VERSION "2026.2.23"

NS_ :

BS_:

BU_: ESC bms_a bms_b

BO_ 2672710145 msg1: 7 ESC
 SG_ TailByte : 48|8@1+ (1,0) [0|255] ""  ESC
 SG_ ThrottleSource : 47|1@1+ (1,0) [0|1] ""  ESC
 SG_ DirectionFlag : 46|1@1+ (1,0) [0|1] ""  ESC
 SG_ CommStatus : 45|1@1+ (1,0) [0|1] ""  ESC
 SG_ OpAmpException : 44|1@1+ (1,0) [0|1] ""  ESC
 SG_ MotorDisconnection : 43|1@1+ (1,0) [0|1] ""  ESC
 SG_ MosShortCircuit : 42|1@1+ (1,0) [0|1] ""  ESC
 SG_ MosOpen : 41|1@1+ (1,0) [0|1] ""  ESC
 SG_ Stall : 40|1@1+ (1,0) [0|1] ""  ESC
 SG_ CapacitorOverheat : 39|1@1+ (1,0) [0|1] ""  ESC
 SG_ MosOverheat : 38|1@1+ (1,0) [0|1] ""  ESC
 SG_ ThrottleNotZero : 37|1@1+ (1,0) [0|1] ""  ESC
 SG_ ThrottleLost : 36|1@1+ (1,0) [0|1] ""  ESC
 SG_ PositioningComplete : 35|1@1+ (1,0) [0|1] ""  ESC
 SG_ Overcurrent : 34|1@1+ (1,0) [0|1] ""  ESC
 SG_ Undervoltage : 33|1@1+ (1,0) [0|1] ""  ESC
 SG_ Overvoltage : 32|1@1+ (1,0) [0|1] ""  ESC
 SG_ PWM : 16|16@1+ (1,0) [0|8191] ""  ESC
 SG_ RPM : 0|16@1+ (1,0) [0|65535] "rpm"  ESC

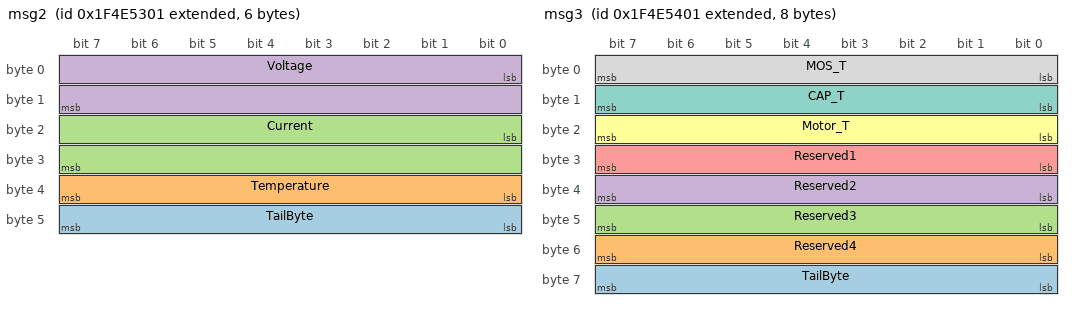
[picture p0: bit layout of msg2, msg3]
BO_ 2672710401 msg2: 6 ESC
 SG_ TailByte : 40|8@1+ (1,0) [0|255] ""  ESC
 SG_ Temperature : 32|8@1+ (1,0) [0|255] "degC"  ESC
 SG_ Current : 16|16@1+ (0.1,0) [0|6553.5] "A"  ESC
 SG_ Voltage : 0|16@1+ (0.1,0) [0|6553.5] "V"  ESC

BO_ 2672710657 msg3: 8 ESC
 SG_ TailByte : 56|8@1+ (1,0) [0|255] ""  ESC
 SG_ Reserved4 : 48|8@1+ (1,0) [0|255] ""  ESC
 SG_ Reserved3 : 40|8@1+ (1,0) [0|255] ""  ESC
 SG_ Reserved2 : 32|8@1+ (1,0) [0|255] ""  ESC
 SG_ Reserved1 : 24|8@1+ (1,0) [0|255] ""  ESC
 SG_ Motor_T : 16|8@1+ (1,0) [0|255] "degC"  ESC
 SG_ CAP_T : 8|8@1+ (1,0) [0|255] "degC"  ESC
 SG_ MOS_T : 0|8@1+ (1,0) [0|255] "degC"  ESC

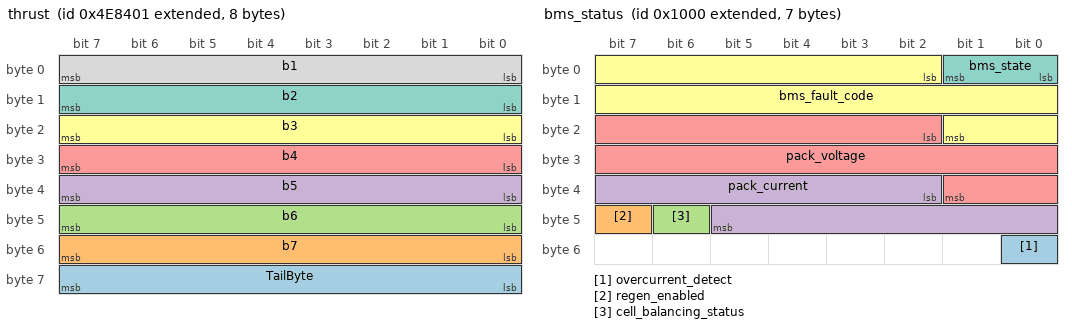
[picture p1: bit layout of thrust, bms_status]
BO_ 2152629249 thrust: 8 ESC
 SG_ TailByte : 56|8@1+ (1,0) [0|255] ""  ESC
 SG_ b7 : 48|8@1+ (1,0) [0|255] "tcode"  ESC
 SG_ b6 : 40|8@1+ (1,0) [0|255] "tcode"  ESC
 SG_ b5 : 32|8@1+ (1,0) [0|255] "tcode"  ESC
 SG_ b4 : 24|8@1+ (1,0) [0|255] "tcode"  ESC
 SG_ b3 : 16|8@1+ (1,0) [0|255] "tcode"  ESC
 SG_ b2 : 8|8@1+ (1,0) [0|255] "tcode"  ESC
 SG_ b1 : 0|8@1+ (1,0) [0|255] "tcode"  ESC

BO_ 2147487744 bms_status: 7 bms_a
 SG_ overcurrent_detect : 48|1@1+ (1,0) [0|0] "bool" Vector__XXX
 SG_ regen_enabled : 47|1@1+ (1,0) [0|0] "bool" Vector__XXX
 SG_ cell_balancing_status : 46|1@1+ (1,0) [0|0] "bool" Vector__XXX
 SG_ pack_current : 34|12@1- (1,0) [0|0] "A" Vector__XXX
 SG_ pack_voltage : 18|16@1+ (1,0) [0|0] "V" Vector__XXX
 SG_ bms_fault_code : 2|16@1+ (1,0) [0|0] "" Vector__XXX
 SG_ bms_state : 0|2@1+ (1,0) [0|0] "" Vector__XXX

BO_ 17 bms_status_b: 1 bms_b
 SG_ bms_state_b : 0|2@1+ (1,0) [0|0] "" Vector__XXX

BO_ 2147488000 bms_status_b_ex: 1 bms_b
 SG_ bms_state_b : 0|2@1+ (1,0) [0|0] "" Vector__XXX

BO_ 2147488003 bms_status_b_ex_e: 1 bms_b
 SG_ bms_state_b : 0|2@1+ (1,0) [0|0] "" Vector__XXX

BA_DEF_ BO_  "GenMsgCycleTime" INT 0 65535;
BA_DEF_DEF_  "GenMsgCycleTime" 0;
BA_ "GenMsgCycleTime" BO_ 2147487744 10.0;
BA_ "GenMsgCycleTime" BO_ 17 10.0;
BA_ "GenMsgCycleTime" BO_ 2147488000 10.0;
BA_ "GenMsgCycleTime" BO_ 2147488003 10.0;
